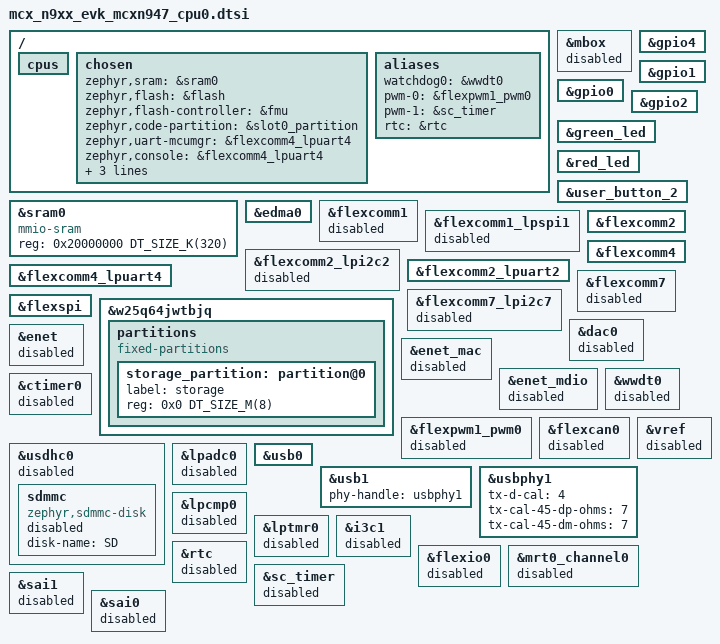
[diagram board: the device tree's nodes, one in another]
/*
 * Copyright 2024-2025 NXP
 *
 * SPDX-License-Identifier: Apache-2.0
 */

/* Common dts file to enable supported features for CPU 0.
 * This file is included by both the default variant
 * which is run from internal flash and the QSPI variant.
 */
/dts-v1/;

#include <nxp/nxp_mcxn94x.dtsi>
#include "mcx_n9xx_evk.dtsi"

/ {
	cpus {
		/delete-node/ cpu@1;
	};

	chosen {
		zephyr,sram = &sram0;
		zephyr,flash = &flash;
		zephyr,flash-controller = &fmu;
		zephyr,code-partition = &slot0_partition;
		zephyr,uart-mcumgr = &flexcomm4_lpuart4;
		zephyr,console = &flexcomm4_lpuart4;
		zephyr,shell-uart = &flexcomm4_lpuart4;
		zephyr,canbus = &flexcan0;
		zephyr,code-cpu1-partition = &slot1_partition;
	};

	aliases{
		watchdog0 = &wwdt0;
		pwm-0 = &flexpwm1_pwm0;
		pwm-1 = &sc_timer;
		rtc = &rtc;
	};
};

/*
 * Default for this board is to allocate SRAM0-5 to cpu0 but the
 * application can have an application specific device tree to
 * allocate the SRAM0-7 differently.
 *
 * For example, SRAM0-6 could be allocated to cpu0 with only SRAM7
 * for cpu1. This would require the value of sram0 to have a DT_SIZE_K
 * of 384. You would have to make updates to cpu1 sram settings as well.
 */
&sram0 {
	compatible = "mmio-sram";
	reg = <0x20000000 DT_SIZE_K(320)>;
};

&mbox {
	status = "disabled";
};

&gpio4 {
	status = "okay";
};

&gpio1 {
	status = "okay";
};

&gpio0 {
	status = "okay";
};

&gpio2 {
	status = "okay";
};

&green_led {
	status = "okay";
};

&red_led {
	status = "okay";
};

&user_button_2 {
	status = "okay";
};

&edma0 {
	status = "okay";
};

&flexcomm1 {
	status = "disabled";
};

&flexcomm1_lpspi1 {
	status = "disabled";
};

&flexcomm2 {
	status = "okay";
};

&flexcomm2_lpi2c2 {
	status = "disabled";
};

/*
 *LPFLEXCOMM supports UART and I2C on the same instance, enable this for
 * LFLEXCOMM2
 */
&flexcomm2_lpuart2 {
	status = "okay";
};

&flexcomm4 {
	status = "okay";
};

&flexcomm4_lpuart4 {
	status = "okay";
};

&flexcomm7 {
	status = "disabled";
};

&flexcomm7_lpi2c7 {
	status = "disabled";
};

&flexspi {
	status = "okay";
};

&w25q64jwtbjq {
	status = "okay";
	partitions {
		compatible = "fixed-partitions";
		#address-cells = <1>;
		#size-cells = <1>;
		storage_partition: partition@0 {
			label = "storage";
			reg = <0x0 DT_SIZE_M(8)>;
		};
	};
};

&dac0 {
	status = "disabled";
};

&enet {
	status = "disabled";
};

&enet_mac {
	status = "disabled";
};

&enet_mdio {
	status = "disabled";
};

&wwdt0 {
	status = "disabled";
};

&flexpwm1_pwm0 {
	status = "disabled";
};

&flexcan0 {
	status = "disabled";
};

&ctimer0 {
	status = "disabled";
};

&usdhc0 {
	status = "disabled";
	sdmmc {
		compatible = "zephyr,sdmmc-disk";
		disk-name = "SD";
		status = "disabled";
	};
};

&vref {
	status = "disabled";
};

&lpadc0 {
	status = "disabled";
};

&usb0 {
	status = "okay";
};

zephyr_udc0: &usb1 {
	status = "okay";
	phy-handle = <&usbphy1>;
};

&usbphy1 {
	status = "okay";
	tx-d-cal = <4>;
	tx-cal-45-dp-ohms = <7>;
	tx-cal-45-dm-ohms = <7>;
};

&lpcmp0 {
	status = "disabled";
};

&lptmr0 {
	status = "disabled";
};

&i3c1 {
	status = "disabled";
};

&flexio0 {
	status = "disabled";
};

&mrt0_channel0 {
	status = "disabled";
};

&rtc {
	status = "disabled";
};

&sc_timer {
	status = "disabled";
};

&sai1 {
	status = "disabled";
};
&sai0 {
	status = "disabled";
};
